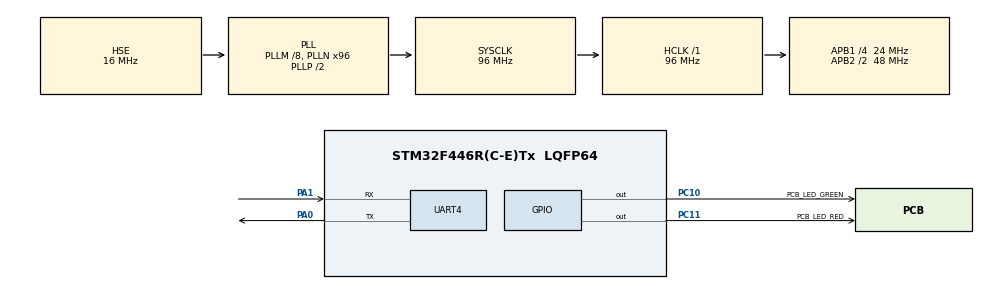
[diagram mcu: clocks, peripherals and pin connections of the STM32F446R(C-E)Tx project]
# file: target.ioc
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Mcu.Family=STM32F4
Mcu.Name=STM32F446R(C-E)Tx
Mcu.Package=LQFP64
NVIC.PVD_IRQn=true\:0\:0\:false\:false\:true\:true\:true\:true
NVIC.PriorityGroup=NVIC_PRIORITYGROUP_4
PA0-WKUP.Mode=Asynchronous
PA0-WKUP.Signal=UART4_TX
PA1.Mode=Asynchronous
PA1.Signal=UART4_RX
PA13.GPIO_Label=SWDIO
PA13.Mode=Serial_Wire
PA13.Signal=SYS_JTMS-SWDIO
PA14.GPIO_Label=SWCLK
PA14.Mode=Serial_Wire
PA14.Signal=SYS_JTCK-SWCLK
PB8.GPIO_Label=CAN_RX
PB8.Signal=CAN1_RX
PB9.GPIO_Label=CAN_TX
PB9.Signal=CAN1_TX
PC10.GPIO_Label=PCB_LED_GREEN
PC10.Signal=GPIO_Output
PC11.GPIO_Label=PCB_LED_RED
PC11.Signal=GPIO_Output
PH0-OSC_IN.GPIO_Label=OSC_IN
PH0-OSC_IN.Mode=HSE-External-Oscillator
PH0-OSC_IN.Signal=RCC_OSC_IN
PH1-OSC_OUT.GPIO_Label=OSC_OUT
PH1-OSC_OUT.Mode=HSE-External-Oscillator
PH1-OSC_OUT.Signal=RCC_OSC_OUT
ProjectManager.HeapSize=0x200
ProjectManager.StackSize=0x400
ProjectManager.TargetToolchain=CMake
RCC.AHBFreq_Value=96000000
RCC.APB1CLKDivider=RCC_HCLK_DIV4
RCC.APB1Freq_Value=24000000
RCC.APB1TimFreq_Value=48000000
RCC.APB2CLKDivider=RCC_HCLK_DIV2
RCC.APB2Freq_Value=48000000
RCC.APB2TimFreq_Value=96000000
RCC.CortexFreq_Value=96000000
RCC.HCLKFreq_Value=96000000
RCC.HSE_VALUE=16000000
RCC.PLLM=8
RCC.PLLN=96
RCC.PLLQ=4
RCC.PLLSourceVirtual=RCC_PLLSOURCE_HSE
RCC.SYSCLKFreq_VALUE=96000000
RCC.SYSCLKSource=RCC_SYSCLKSOURCE_PLLCLK
RCC.USBFreq_Value=48000000
RCC.VCOOutputFreq_Value=192000000
UART4.VirtualMode=Asynchronous
board=custom

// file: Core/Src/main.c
/* USER CODE BEGIN Header */
/**
 ******************************************************************************
 * @file           : main.c
 * @brief          : Main program body
 ******************************************************************************
 * @attention
 *
 * Copyright (c) 2026 STMicroelectronics.
 * All rights reserved.
 *
 * This software is licensed under terms that can be found in the LICENSE file
 * in the root directory of this software component.
 * If no LICENSE file comes with this software, it is provided AS-IS.
 *
 ******************************************************************************
 */
/* USER CODE END Header */
#include "main.h"
#include "gpio.h"
#include "stm32f4xx_hal_def.h"
#include "stm32f4xx_hal_uart.h"
#include "usart.h"
#include <string.h>

void SystemClock_Config(void);

int main(void)
{

    /* MCU Configuration--------------------------------------------------------*/

    /* Reset of all peripherals, Initializes the Flash interface and the Systick. */
    HAL_Init();

    /* Configure the system clock */
    SystemClock_Config();

    /* Initialize all configured peripherals */
    MX_GPIO_Init();
    MX_UART4_Init();
    /* USER CODE BEGIN 2 */
    const char message[] = "Hello World!\n";
    /* USER CODE END 2 */

    /* Infinite loop */
    /* USER CODE BEGIN WHILE */
    while (1)
    {
        HAL_GPIO_TogglePin(PCB_LED_GREEN_GPIO_Port, PCB_LED_GREEN_Pin);
        HAL_Delay(100);
        HAL_UART_Transmit(&huart4, (uint8_t *)(message), strlen(message), HAL_MAX_DELAY);
        /* USER CODE END WHILE */

    }
}

void SystemClock_Config(void)
{
    RCC_OscInitTypeDef RCC_OscInitStruct = {0};
    RCC_ClkInitTypeDef RCC_ClkInitStruct = {0};

    /** Configure the main internal regulator output voltage
     */
    __HAL_RCC_PWR_CLK_ENABLE();
    __HAL_PWR_VOLTAGESCALING_CONFIG(PWR_REGULATOR_VOLTAGE_SCALE3);

    /** Initializes the RCC Oscillators according to the specified parameters
     * in the RCC_OscInitTypeDef structure.
     */
    RCC_OscInitStruct.OscillatorType = RCC_OSCILLATORTYPE_HSE;
    RCC_OscInitStruct.HSEState = RCC_HSE_ON;
    RCC_OscInitStruct.PLL.PLLState = RCC_PLL_ON;
    RCC_OscInitStruct.PLL.PLLSource = RCC_PLLSOURCE_HSE;
    RCC_OscInitStruct.PLL.PLLM = 8;
    RCC_OscInitStruct.PLL.PLLN = 96;
    RCC_OscInitStruct.PLL.PLLP = RCC_PLLP_DIV2;
    RCC_OscInitStruct.PLL.PLLQ = 4;
    RCC_OscInitStruct.PLL.PLLR = 2;
    if (HAL_RCC_OscConfig(&RCC_OscInitStruct) != HAL_OK)
    {
        Error_Handler();
    }

    /** Initializes the CPU, AHB and APB buses clocks
     */
    RCC_ClkInitStruct.ClockType = RCC_CLOCKTYPE_HCLK | RCC_CLOCKTYPE_SYSCLK | RCC_CLOCKTYPE_PCLK1 | RCC_CLOCKTYPE_PCLK2;
    RCC_ClkInitStruct.SYSCLKSource = RCC_SYSCLKSOURCE_PLLCLK;
    RCC_ClkInitStruct.AHBCLKDivider = RCC_SYSCLK_DIV1;
    RCC_ClkInitStruct.APB1CLKDivider = RCC_HCLK_DIV4;
    RCC_ClkInitStruct.APB2CLKDivider = RCC_HCLK_DIV2;

    if (HAL_RCC_ClockConfig(&RCC_ClkInitStruct, FLASH_LATENCY_3) != HAL_OK)
    {
        Error_Handler();
    }
}

void Error_Handler(void)
{
    __disable_irq();
    while (1)
    {
    }
}
#ifdef USE_FULL_ASSERT
/**
 * @brief  Reports the name of the source file and the source line number
 *         where the assert_param error has occurred.
 * @param  file: pointer to the source file name
 * @param  line: assert_param error line source number
 * @retval None
 */
void assert_failed(uint8_t *file, uint32_t line)
{
    /* USER CODE BEGIN 6 */
    /* User can add his own implementation to report the file name and line
       number, ex: printf("Wrong parameters value: file %s on line %d\r\n", file,
       line) */
    /* USER CODE END 6 */
}
#endif /* USE_FULL_ASSERT */
